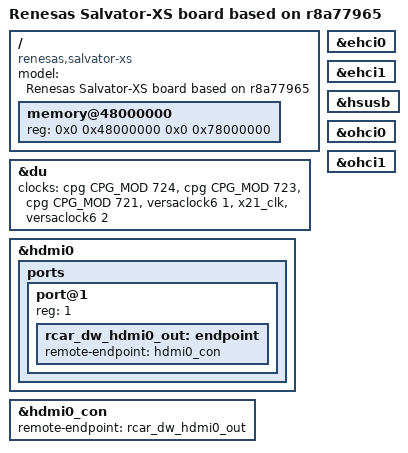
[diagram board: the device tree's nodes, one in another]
// SPDX-License-Identifier: GPL-2.0
/*
 * Device Tree Source for the Salvator-XS board
 *
 * Copyright (C) 2018-2019 Renesas Electronics Corporation
 */

/dts-v1/;
#include "r8a77965.dtsi"
#include "salvator-xs.dtsi"

/ {
	model = "Renesas Salvator-XS board based on r8a77965";
	compatible = "renesas,salvator-xs", "renesas,r8a77965";

	memory@48000000 {
		device_type = "memory";
		/* first 128MB is reserved for secure area. */
		reg = <0x0 0x48000000 0x0 0x78000000>;
	};
};

&du {
	clocks = <&cpg CPG_MOD 724>,
		 <&cpg CPG_MOD 723>,
		 <&cpg CPG_MOD 721>,
		 <&versaclock6 1>,
		 <&x21_clk>,
		 <&versaclock6 2>;
	clock-names = "du.0", "du.1", "du.3",
		      "dclkin.0", "dclkin.1", "dclkin.3";
};

&hdmi0 {
	status = "okay";

	ports {
		port@1 {
			reg = <1>;
			rcar_dw_hdmi0_out: endpoint {
				remote-endpoint = <&hdmi0_con>;
			};
		};
	};
};

&hdmi0_con {
	remote-endpoint = <&rcar_dw_hdmi0_out>;
};

&ehci0 {
	status = "okay";
};

&ehci1 {
	status = "okay";
};

&hsusb {
	status = "okay";
};

&ohci0 {
	status = "okay";
};

&ohci1 {
	status = "okay";
};
